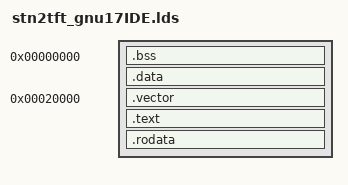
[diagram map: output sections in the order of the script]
/* Linker Script file generated by Gnu17 Plug-in for Eclipse */
OUTPUT_FORMAT("elf32-c17", "elf32-c17", "elf32-c17")
OUTPUT_ARCH(c17)
SEARCH_DIR(.);

SECTIONS
{

	/* stack pointer symbols */
	__START_stack = 0x000FC0;

	/* location counter */
	. = 0x0;

	/* section information */
	.bss 0x000000 : 
	  {
	   __START_bss = . ;
	   main.o(.bss)
	   stn2tft.o(.bss)
	   vector.o(.bss)
	   C:/EPSON/GNU17/lib/24bit/libstdio.a(.bss)
	   C:/EPSON/GNU17/lib/24bit/libc.a(.bss)
	   C:/EPSON/GNU17/lib/24bit/libgcc.a(.bss)
	   C:/EPSON/GNU17/lib/24bit/libc.a(.bss)
	  }
	  __END_bss = . ;

	.data __END_bss : AT( __END_rodata )
	  {
	   __START_data = . ;
	   main.o(.data)
	   stn2tft.o(.data)
	   vector.o(.data)
	   C:/EPSON/GNU17/lib/24bit/libstdio.a(.data)
	   C:/EPSON/GNU17/lib/24bit/libc.a(.data)
	   C:/EPSON/GNU17/lib/24bit/libgcc.a(.data)
	   C:/EPSON/GNU17/lib/24bit/libc.a(.data)
	  }
	  __END_data = . ;

	.vector 0x020000 : 
	  {
	   __START_vector = . ;
	   vector.o(.rodata)
	  }
	  __END_vector = . ;

	.text __END_vector : 
	  {
	   __START_text = . ;
	   main.o(.text)
	   stn2tft.o(.text)
	   vector.o(.text)
	   C:/EPSON/GNU17/lib/24bit/libstdio.a(.text)
	   C:/EPSON/GNU17/lib/24bit/libc.a(.text)
	   C:/EPSON/GNU17/lib/24bit/libgcc.a(.text)
	   C:/EPSON/GNU17/lib/24bit/libc.a(.text)
	  }
	  __END_text = . ;

	.rodata __END_text : 
	  {
	   __START_rodata = . ;
	   main.o(.rodata)
	   stn2tft.o(.rodata)
	   C:/EPSON/GNU17/lib/24bit/libstdio.a(.rodata)
	   C:/EPSON/GNU17/lib/24bit/libc.a(.rodata)
	   C:/EPSON/GNU17/lib/24bit/libgcc.a(.rodata)
	   C:/EPSON/GNU17/lib/24bit/libc.a(.rodata)
	  }
	  __END_rodata = . ;

	/* load address symbols */
	__START_data_lma = LOADADDR( .data );
	__END_data_lma = __START_data_lma + SIZEOF( .data );
}
